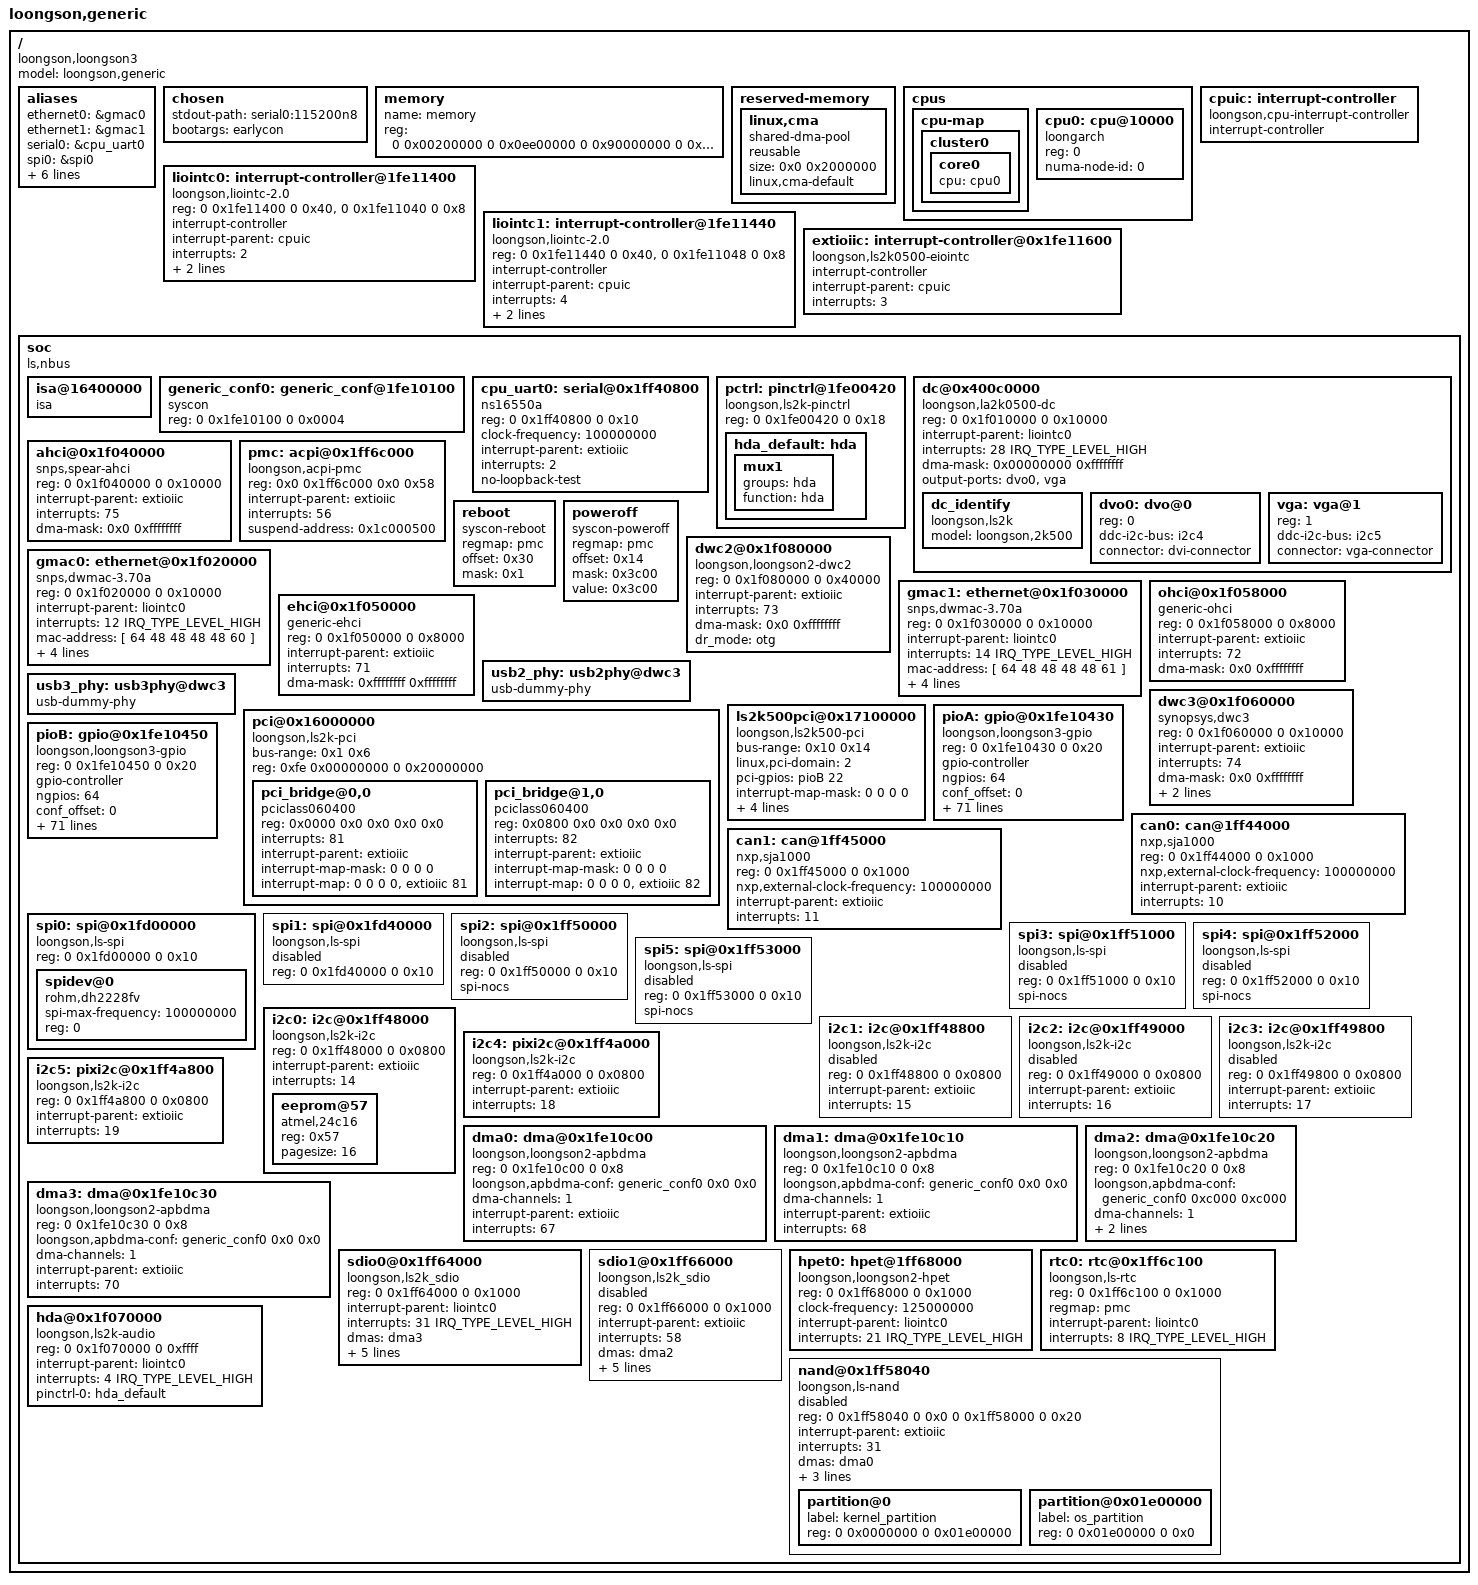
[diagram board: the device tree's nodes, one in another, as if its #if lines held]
#include <dt-bindings/interrupt-controller/irq.h>
#include <dt-bindings/gpio/gpio.h>

/dts-v1/;
/ {
	model = "loongson,generic";
	compatible = "loongson,loongson3";
	#address-cells = <2>;
	#size-cells = <2>;

	aliases {
		ethernet0 = &gmac0;
		ethernet1 = &gmac1;
		serial0 = &cpu_uart0;
		spi0 = &spi0;
		i2c0 = &i2c0;
		i2c1 = &i2c1;
		i2c2 = &i2c2;
		i2c3 = &i2c3;
		i2c4 = &i2c4;
		i2c5 = &i2c5;
	};

	chosen {
		stdout-path = "serial0:115200n8";
		bootargs = "earlycon";
	};

	memory {
		name = "memory";
		device_type = "memory";
		reg =  <0 0x00200000 0 0x0ee00000
			0 0x90000000 0 0x60000000>;
	};

	reserved-memory {
		#address-cells = <2>;
		#size-cells = <2>;
		ranges;

		linux,cma {
			compatible = "shared-dma-pool";
			reusable;
			size = <0x0 0x2000000>;
			linux,cma-default;
		};
	};

	cpus {
		#address-cells = <1>;
		#size-cells = <0>;
		cpu-map {
			cluster0 {
				core0 {
					cpu = <&cpu0>;
				};
			};
		};


		cpu0: cpu@10000 {
			device_type = "cpu";
			compatible = "loongarch";
			reg=<0>;
			numa-node-id = <0>;
		};

	};

	cpuic: interrupt-controller {
		compatible = "loongson,cpu-interrupt-controller";
		interrupt-controller;
		#interrupt-cells = <1>;
	};

	liointc0: interrupt-controller@1fe11400 {
		compatible = "loongson,liointc-2.0";
		reg = <0 0x1fe11400 0 0x40>,
		      <0 0x1fe11040 0 0x8>;
		reg-names = "main", "isr0";

		interrupt-controller;
		#interrupt-cells = <2>;
		interrupt-parent = <&cpuic>;
		interrupts = <2>;
		interrupt-names = "int0";

		loongson,parent_int_map = <0xffffffff>, /* int0 */
					<0x00000000>, /* int1 */
					<0x00000000>, /* int2 */
					<0x00000000>; /* int3 */
	};

	liointc1: interrupt-controller@1fe11440 {
		compatible = "loongson,liointc-2.0";
		reg = <0 0x1fe11440 0 0x40>,
		      <0 0x1fe11048 0 0x8>;
		reg-names = "main", "isr0";

		interrupt-controller;
		#interrupt-cells = <2>;

		interrupt-parent = <&cpuic>;
		interrupts = <4>;
		interrupt-names = "int2";

		loongson,parent_int_map = <0x00000000>, /* int0 */
					<0x00000000>, /* int1 */
					<0xffffffff>, /* int2 */
					<0x00000000>; /* int3 */
	};

	extioiic: interrupt-controller@0x1fe11600 {
		compatible = "loongson,ls2k0500-eiointc";
		interrupt-controller;
		#interrupt-cells = <1>;
		interrupt-parent = <&cpuic>;
		interrupts = <3>;
	};

	soc {
		compatible = "ls,nbus", "simple-bus";
		#address-cells = <2>;
		#size-cells = <2>;
		ranges = <0 0x10000000 0 0x10000000 0 0x10000000
			0 0x2000000  0 0x2000000  0 0x2000000
			0 0x20000000 0 0x20000000 0 0x10000000
			0 0x40000000 0 0x40000000 0 0x40000000
			0xfe 0x00000000 0xfe 0x00000000 0 0x40000000>;

		isa@16400000 {
			compatible = "isa";
			#size-cells = <1>;
			#address-cells = <2>;
			ranges = <1 0 0 0x16400000 0x4000>;
		};

		generic_conf0: generic_conf@1fe10100 {
			compatible = "syscon";
			reg = <0 0x1fe10100 0 0x0004>;
		};

		cpu_uart0: serial@0x1ff40800 {
			compatible = "ns16550a";
			reg = <0 0x1ff40800 0 0x10>;
			clock-frequency = <100000000>;
			interrupt-parent = <&extioiic>;
			interrupts = <2>;
			no-loopback-test;
		};
		pctrl:pinctrl@1fe00420 {
			compatible = "loongson,ls2k-pinctrl";
			reg = <0 0x1fe00420 0 0x18>;
			hda_default:hda {
				mux1 {
					groups ="hda";
					function ="hda";
				};
			};
		};

		dc@0x400c0000 {
			compatible = "loongson,la2k0500-dc", "loongson,display-subsystem";
			reg = <0 0x1f010000 0 0x10000>;
			interrupt-parent = <&liointc0>;
			interrupts = <28 IRQ_TYPE_LEVEL_HIGH>;
			dma-mask = <0x00000000 0xffffffff>;

			output-ports = <&dvo0 &vga>;

			#address-cells = <1>;
			#size-cells = <0>;

			dc_identify {
				model = "loongson,2k500";
				compatible = "loongson,ls2k";
			};

			dvo0: dvo@0 {
				/* 0 for connector 0 (DVO0) */
				reg = <0>;
				ddc-i2c-bus = <&i2c4>;
				connector = "dvi-connector";
				status = "ok";
			};

			vga: vga@1 {
				/* 1 for connector 1 (DVO1) */
				reg = <1>;
				ddc-i2c-bus = <&i2c5>;
				connector = "vga-connector";
				status = "ok";
			};
		};

		ahci@0x1f040000 {
			compatible = "snps,spear-ahci";
			reg = <0 0x1f040000 0 0x10000>;
			interrupt-parent = <&extioiic>;
			interrupts = <75>;
			dma-mask = <0x0 0xffffffff>;
		};

		pmc: acpi@0x1ff6c000 {
			compatible = "loongson,acpi-pmc", "syscon";
			reg = <0x0 0x1ff6c000 0x0 0x58>;
			interrupt-parent = <&extioiic>;
			interrupts = <56>;
			suspend-address = <0x1c000500>;
		};

		reboot {
			compatible ="syscon-reboot";
			regmap = <&pmc>;
			offset = <0x30>;
			mask = <0x1>;
		};

		poweroff {
			compatible ="syscon-poweroff";
			regmap = <&pmc>;
			offset = <0x14>;
			mask = <0x3c00>;
			value = <0x3c00>;
		};

		dwc2@0x1f080000 {
			compatible = "loongson,loongson2-dwc2";
			reg = <0 0x1f080000 0 0x40000>;
			interrupt-parent = <&extioiic>;
			interrupts = <73>;
			dma-mask = <0x0 0xffffffff>;
			dr_mode = "otg";
			/* Optional for that dr_mode = "host" or dr_mode = "peripheral" */
		};

		gmac0: ethernet@0x1f020000 {
			compatible = "snps,dwmac-3.70a";
			reg = <0 0x1f020000 0 0x10000>;
			interrupt-parent = <&liointc0>;
			interrupts = <12 IRQ_TYPE_LEVEL_HIGH>;
			interrupt-names = "macirq";
			mac-address = [ 64 48 48 48 48 60 ];/* [>mac 64:48:48:48:48:60 <]*/
			phy-mode = "rgmii";
			bus_id = <0x0>;
			phy_addr = <0xffffffff>;
			dma-mask = <0xffffffff 0xffffffff>;
		};

		gmac1: ethernet@0x1f030000 {
			compatible = "snps,dwmac-3.70a";
			reg = <0 0x1f030000 0 0x10000>;
			interrupt-parent = <&liointc0>;
			interrupts = <14 IRQ_TYPE_LEVEL_HIGH>;
			interrupt-names = "macirq";
			mac-address = [ 64 48 48 48 48 61 ];/* [>mac 64:48:48:48:48:61 <]*/
			phy-mode = "rgmii";
			bus_id = <0x1>;
			phy_addr = <0xffffffff>;
			dma-mask = <0xffffffff 0xffffffff>;
		};

		ohci@0x1f058000 {
			compatible = "generic-ohci";
			reg = <0 0x1f058000 0 0x8000>;
			interrupt-parent = <&extioiic>;
			interrupts = <72>;
			dma-mask = <0x0 0xffffffff>;
		};

		ehci@0x1f050000 {
			compatible = "generic-ehci";
			reg = <0 0x1f050000 0 0x8000>;
			interrupt-parent = <&extioiic>;
			interrupts = <71>;
			dma-mask = <0xffffffff 0xffffffff>;
		};

		usb2_phy: usb2phy@dwc3 {
			compatible = "usb-dummy-phy";
		};

		usb3_phy: usb3phy@dwc3 {
			compatible = "usb-dummy-phy";
		};

		dwc3@0x1f060000 {
			compatible = "synopsys,dwc3";
			reg = <0 0x1f060000 0 0x10000>;
			interrupt-parent = <&extioiic>;
			interrupts = <74>;
			dma-mask = <0x0 0xffffffff>;
			usb-phy = <&usb2_phy>, <&usb3_phy>;
			dr_mode = "host";
		};

		pci@0x16000000 {
			compatible = "loongson,ls2k-pci";
			#interrupt-cells = <1>;
			bus-range = <0x1 0x6>;
			#size-cells = <2>;
			#address-cells = <3>;

			reg = < 0xfe 0x00000000 0 0x20000000>;
			ranges = <0x02000000 0 0x40000000 0 0x40000000 0 0x40000000
				  0x01000000 0 0x00004000 0 0x16404000 0x0 0x4000>;

			pci_bridge@0,0 {
				compatible = "pciclass060400",
						   "pciclass0604";

				reg = <0x0000 0x0 0x0 0x0 0x0>;
				interrupts = <81>;
				interrupt-parent = <&extioiic>;

				#interrupt-cells = <1>;
				interrupt-map-mask = <0 0 0 0>;
				interrupt-map = <0 0 0 0 &extioiic 81>;
			};
			pci_bridge@1,0 {
				compatible = "pciclass060400",
						   "pciclass0604";

				reg = <0x0800 0x0 0x0 0x0 0x0>;
				interrupts = <82>;
				interrupt-parent = <&extioiic>;

				#interrupt-cells = <1>;
				interrupt-map-mask = <0 0 0 0>;
				interrupt-map = <0 0 0 0 &extioiic 82>;
			};
		};

#ifdef LS2K500_HAVE_PCI
		ls2k500pci@0x17100000 {
			compatible = "loongson,ls2k500-pci";
			#interrupt-cells = <1>;
			bus-range = <0x10 0x14>;
			#size-cells = <2>;
			#address-cells = <3>;
			linux,pci-domain = <2>;

#if 0
			pci-gpios = <&pioA 0 0>, <&pioA 1 0>;
			interrupt-map-mask = <0xf800 0 0 7>;
			interrupt-map =
				<0x0f8000 0 0 1 &liointc1 26 IRQ_TYPE_LEVEL_HIGH>, /* Slot 9 */
				<0x0f8000 0 0 2 &liointc1 26 IRQ_TYPE_LEVEL_HIGH>,
				<0x0f8000 0 0 3 &liointc1 26 IRQ_TYPE_LEVEL_HIGH>,
				<0x0f8000 0 0 4 &liointc1 26 IRQ_TYPE_LEVEL_HIGH>,
				<0x0f8800 0 0 1 &liointc1 26 IRQ_TYPE_LEVEL_HIGH>, /* Slot 10 */
				<0x0f8800 0 0 2 &liointc1 26 IRQ_TYPE_LEVEL_HIGH>,
				<0x0f8800 0 0 3 &liointc1 26 IRQ_TYPE_LEVEL_HIGH>,
				<0x0f8800 0 0 4 &liointc1 26 IRQ_TYPE_LEVEL_HIGH>;
#else
				pci-gpios = <&pioB 22 0>;
				interrupt-map-mask = <0 0 0 0>;
				interrupt-map = <0 0 0 0 &liointc1 28 IRQ_TYPE_LEVEL_HIGH>;
#endif
				reg = < 0x0 0x17100000 0 0x10000
					0x0 0x17110000 0 0x10000
					0x0 0x1fe11100 0 0x100 >;
			ranges = <0x02000000 0 0x20000000 0 0x20000000 0 0x10000000
				  0x01000000 0 0x00008000 0 0x17008000 0x0 0x4000>;
		};
#endif

		pioA:gpio@0x1fe10430 {
			compatible = "loongson,loongson3-gpio";
			reg = <0 0x1fe10430 0 0x20>;
			gpio-controller;
			#gpio-cells = <2>;
			ngpios = <64>;
			conf_offset = <0>;
			out_offset = <0x10>;
			in_offset = <0x8>;
			in_start_bit = <0>;
			inten_offset = <0xb0>;
			gpio_base = <0>;
			support_irq;
			interrupts-extended =
				/*
				 * Every 32 gpios share a interrupt line. We need to disable
				 * unnecessary GPIO interrupts in the firmware.
				 */
				<&liointc1 26 IRQ_TYPE_LEVEL_HIGH>,<&liointc1 26 IRQ_TYPE_LEVEL_HIGH>,<&liointc1 26 IRQ_TYPE_LEVEL_HIGH>,<&liointc1 26 IRQ_TYPE_LEVEL_HIGH>,
				<&liointc1 26 IRQ_TYPE_LEVEL_HIGH>,<&liointc1 26 IRQ_TYPE_LEVEL_HIGH>,<&liointc1 26 IRQ_TYPE_LEVEL_HIGH>,<&liointc1 26 IRQ_TYPE_LEVEL_HIGH>,
				<&liointc1 26 IRQ_TYPE_LEVEL_HIGH>,<&liointc1 26 IRQ_TYPE_LEVEL_HIGH>,<&liointc1 26 IRQ_TYPE_LEVEL_HIGH>,<&liointc1 26 IRQ_TYPE_LEVEL_HIGH>,
				<&liointc1 26 IRQ_TYPE_LEVEL_HIGH>,<&liointc1 26 IRQ_TYPE_LEVEL_HIGH>,<&liointc1 26 IRQ_TYPE_LEVEL_HIGH>,<&liointc1 26 IRQ_TYPE_LEVEL_HIGH>,
				<&liointc1 26 IRQ_TYPE_LEVEL_HIGH>,<&liointc1 26 IRQ_TYPE_LEVEL_HIGH>,<&liointc1 26 IRQ_TYPE_LEVEL_HIGH>,<&liointc1 26 IRQ_TYPE_LEVEL_HIGH>,
				<&liointc1 26 IRQ_TYPE_LEVEL_HIGH>,<&liointc1 26 IRQ_TYPE_LEVEL_HIGH>,<&liointc1 26 IRQ_TYPE_LEVEL_HIGH>,<&liointc1 26 IRQ_TYPE_LEVEL_HIGH>,
				<&liointc1 26 IRQ_TYPE_LEVEL_HIGH>,<&liointc1 26 IRQ_TYPE_LEVEL_HIGH>,<&liointc1 26 IRQ_TYPE_LEVEL_HIGH>,<&liointc1 26 IRQ_TYPE_LEVEL_HIGH>,
				<&liointc1 26 IRQ_TYPE_LEVEL_HIGH>,<&liointc1 26 IRQ_TYPE_LEVEL_HIGH>,<&liointc1 26 IRQ_TYPE_LEVEL_HIGH>,<&liointc1 26 IRQ_TYPE_LEVEL_HIGH>,
				<&liointc1 27 IRQ_TYPE_LEVEL_HIGH>,<&liointc1 27 IRQ_TYPE_LEVEL_HIGH>,<&liointc1 27 IRQ_TYPE_LEVEL_HIGH>,<&liointc1 27 IRQ_TYPE_LEVEL_HIGH>,
				<&liointc1 27 IRQ_TYPE_LEVEL_HIGH>,<&liointc1 27 IRQ_TYPE_LEVEL_HIGH>,<&liointc1 27 IRQ_TYPE_LEVEL_HIGH>,<&liointc1 27 IRQ_TYPE_LEVEL_HIGH>,
				<&liointc1 27 IRQ_TYPE_LEVEL_HIGH>,<&liointc1 27 IRQ_TYPE_LEVEL_HIGH>,<&liointc1 27 IRQ_TYPE_LEVEL_HIGH>,<&liointc1 27 IRQ_TYPE_LEVEL_HIGH>,
				<&liointc1 27 IRQ_TYPE_LEVEL_HIGH>,<&liointc1 27 IRQ_TYPE_LEVEL_HIGH>,<&liointc1 27 IRQ_TYPE_LEVEL_HIGH>,<&liointc1 27 IRQ_TYPE_LEVEL_HIGH>,
				<&liointc1 27 IRQ_TYPE_LEVEL_HIGH>,<&liointc1 27 IRQ_TYPE_LEVEL_HIGH>,<&liointc1 27 IRQ_TYPE_LEVEL_HIGH>,<&liointc1 27 IRQ_TYPE_LEVEL_HIGH>,
				<&liointc1 27 IRQ_TYPE_LEVEL_HIGH>,<&liointc1 27 IRQ_TYPE_LEVEL_HIGH>,<&liointc1 27 IRQ_TYPE_LEVEL_HIGH>,<&liointc1 27 IRQ_TYPE_LEVEL_HIGH>,
				<&liointc1 27 IRQ_TYPE_LEVEL_HIGH>,<&liointc1 27 IRQ_TYPE_LEVEL_HIGH>,<&liointc1 27 IRQ_TYPE_LEVEL_HIGH>,<&liointc1 27 IRQ_TYPE_LEVEL_HIGH>,
				<&liointc1 27 IRQ_TYPE_LEVEL_HIGH>,<&liointc1 27 IRQ_TYPE_LEVEL_HIGH>,<&liointc1 27 IRQ_TYPE_LEVEL_HIGH>,<&liointc1 27 IRQ_TYPE_LEVEL_HIGH>;
		};

		pioB:gpio@0x1fe10450 {
			compatible = "loongson,loongson3-gpio";
			reg = <0 0x1fe10450 0 0x20>;
			gpio-controller;
			#gpio-cells = <2>;
			ngpios = <64>;
			conf_offset = <0>;
			out_offset = <0x10>;
			in_offset = <0x8>;
			in_start_bit = <0>;
			inten_offset = <0x98>;
			gpio_base = <64>;
			support_irq;
			interrupts-extended  =
				/*
				 * Every 32 gpios share a interrupt line. We need to disable
				 * unnecessary GPIO interrupts in the firmware.
				 */
				<&liointc1 28 IRQ_TYPE_LEVEL_HIGH>,<&liointc1 28 IRQ_TYPE_LEVEL_HIGH>,<&liointc1 28 IRQ_TYPE_LEVEL_HIGH>,<&liointc1 28 IRQ_TYPE_LEVEL_HIGH>,
				<&liointc1 28 IRQ_TYPE_LEVEL_HIGH>,<&liointc1 28 IRQ_TYPE_LEVEL_HIGH>,<&liointc1 28 IRQ_TYPE_LEVEL_HIGH>,<&liointc1 28 IRQ_TYPE_LEVEL_HIGH>,
				<&liointc1 28 IRQ_TYPE_LEVEL_HIGH>,<&liointc1 28 IRQ_TYPE_LEVEL_HIGH>,<&liointc1 28 IRQ_TYPE_LEVEL_HIGH>,<&liointc1 28 IRQ_TYPE_LEVEL_HIGH>,
				<&liointc1 28 IRQ_TYPE_LEVEL_HIGH>,<&liointc1 28 IRQ_TYPE_LEVEL_HIGH>,<&liointc1 28 IRQ_TYPE_LEVEL_HIGH>,<&liointc1 28 IRQ_TYPE_LEVEL_HIGH>,
				<&liointc1 28 IRQ_TYPE_LEVEL_HIGH>,<&liointc1 28 IRQ_TYPE_LEVEL_HIGH>,<&liointc1 28 IRQ_TYPE_LEVEL_HIGH>,<&liointc1 28 IRQ_TYPE_LEVEL_HIGH>,
				<&liointc1 28 IRQ_TYPE_LEVEL_HIGH>,<&liointc1 28 IRQ_TYPE_LEVEL_HIGH>,<&liointc1 28 IRQ_TYPE_LEVEL_HIGH>,<&liointc1 28 IRQ_TYPE_LEVEL_HIGH>,
				<&liointc1 28 IRQ_TYPE_LEVEL_HIGH>,<&liointc1 28 IRQ_TYPE_LEVEL_HIGH>,<&liointc1 28 IRQ_TYPE_LEVEL_HIGH>,<&liointc1 28 IRQ_TYPE_LEVEL_HIGH>,
				<&liointc1 28 IRQ_TYPE_LEVEL_HIGH>,<&liointc1 28 IRQ_TYPE_LEVEL_HIGH>,<&liointc1 28 IRQ_TYPE_LEVEL_HIGH>,<&liointc1 28 IRQ_TYPE_LEVEL_HIGH>,
				<&liointc1 29 IRQ_TYPE_LEVEL_HIGH>,<&liointc1 29 IRQ_TYPE_LEVEL_HIGH>,<&liointc1 29 IRQ_TYPE_LEVEL_HIGH>,<&liointc1 29 IRQ_TYPE_LEVEL_HIGH>,
				<&liointc1 29 IRQ_TYPE_LEVEL_HIGH>,<&liointc1 29 IRQ_TYPE_LEVEL_HIGH>,<&liointc1 29 IRQ_TYPE_LEVEL_HIGH>,<&liointc1 29 IRQ_TYPE_LEVEL_HIGH>,
				<&liointc1 29 IRQ_TYPE_LEVEL_HIGH>,<&liointc1 29 IRQ_TYPE_LEVEL_HIGH>,<&liointc1 29 IRQ_TYPE_LEVEL_HIGH>,<&liointc1 29 IRQ_TYPE_LEVEL_HIGH>,
				<&liointc1 29 IRQ_TYPE_LEVEL_HIGH>,<&liointc1 29 IRQ_TYPE_LEVEL_HIGH>,<&liointc1 29 IRQ_TYPE_LEVEL_HIGH>,<&liointc1 29 IRQ_TYPE_LEVEL_HIGH>,
				<&liointc1 29 IRQ_TYPE_LEVEL_HIGH>,<&liointc1 29 IRQ_TYPE_LEVEL_HIGH>,<&liointc1 29 IRQ_TYPE_LEVEL_HIGH>,<&liointc1 29 IRQ_TYPE_LEVEL_HIGH>,
				<&liointc1 29 IRQ_TYPE_LEVEL_HIGH>,<&liointc1 29 IRQ_TYPE_LEVEL_HIGH>,<&liointc1 29 IRQ_TYPE_LEVEL_HIGH>,<&liointc1 29 IRQ_TYPE_LEVEL_HIGH>,
				<&liointc1 29 IRQ_TYPE_LEVEL_HIGH>,<&liointc1 29 IRQ_TYPE_LEVEL_HIGH>,<&liointc1 29 IRQ_TYPE_LEVEL_HIGH>,<&liointc1 29 IRQ_TYPE_LEVEL_HIGH>,
				<&liointc1 29 IRQ_TYPE_LEVEL_HIGH>,<&liointc1 29 IRQ_TYPE_LEVEL_HIGH>,<&liointc1 29 IRQ_TYPE_LEVEL_HIGH>,<&liointc1 29 IRQ_TYPE_LEVEL_HIGH>;
		};

		can0: can@1ff44000 {
			compatible = "nxp,sja1000";
			reg = <0 0x1ff44000 0 0x1000>;
			nxp,external-clock-frequency = <100000000>;
			interrupt-parent = <&extioiic>;
			interrupts = <10>;
		};

		can1: can@1ff45000 {
			compatible = "nxp,sja1000";
			reg = <0 0x1ff45000 0 0x1000>;
			nxp,external-clock-frequency = <100000000>;
			interrupt-parent = <&extioiic>;
			interrupts = <11>;
		};

		spi0: spi@0x1fd00000 {
			compatible = "loongson,ls-spi";
			#address-cells = <1>;
			#size-cells = <0>;
			reg = <0 0x1fd00000 0 0x10>;
			spidev@0 {
				compatible = "rohm,dh2228fv";
				spi-max-frequency = <100000000>;
				reg = <0>;
			};
		};

		spi1: spi@0x1fd40000 {
			compatible = "loongson,ls-spi";
			reg = <0 0x1fd40000 0 0x10>;
			status = "disabled";
		};

		/* SPI2~5 has only one CS, which is set by SPCS */
		spi2: spi@0x1ff50000 {
			compatible = "loongson,ls-spi";
			reg = <0 0x1ff50000 0 0x10>;
			spi-nocs;
			status = "disabled";
		};

		spi3: spi@0x1ff51000 {
			compatible = "loongson,ls-spi";
			reg = <0 0x1ff51000 0 0x10>;
			spi-nocs;
			status = "disabled";
		};

		spi4: spi@0x1ff52000 {
			compatible = "loongson,ls-spi";
			reg = <0 0x1ff52000 0 0x10>;
			spi-nocs;
			status = "disabled";
		};

		spi5: spi@0x1ff53000 {
			compatible = "loongson,ls-spi";
			reg = <0 0x1ff53000 0 0x10>;
			spi-nocs;
			status = "disabled";
		};

		i2c0: i2c@0x1ff48000 {
			compatible = "loongson,ls2k-i2c";
			#address-cells = <1>;
			#size-cells = <0>;
			reg = <0 0x1ff48000 0 0x0800>;
			interrupt-parent = <&extioiic>;
			interrupts = <14>;
			eeprom@57 {
				compatible = "atmel,24c16";
				reg = <0x57>;
				pagesize = <16>;
			};
		};

		i2c1: i2c@0x1ff48800 {
			compatible = "loongson,ls2k-i2c";
			reg = <0 0x1ff48800 0 0x0800>;
			interrupt-parent = <&extioiic>;
			interrupts = <15>;
			status = "disabled";
		};

		i2c2: i2c@0x1ff49000 {
			compatible = "loongson,ls2k-i2c";
			reg = <0 0x1ff49000 0 0x0800>;
			interrupt-parent = <&extioiic>;
			interrupts = <16>;
			status = "disabled";
		};

		i2c3: i2c@0x1ff49800 {
			compatible = "loongson,ls2k-i2c";
			reg = <0 0x1ff49800 0 0x0800>;
			interrupt-parent = <&extioiic>;
			interrupts = <17>;
			status = "disabled";
		};

		i2c4: pixi2c@0x1ff4a000{
			compatible = "loongson,ls2k-i2c";
			reg = <0 0x1ff4a000 0 0x0800>;
			interrupt-parent = <&extioiic>;
			interrupts = <18>;
		};

		i2c5: pixi2c@0x1ff4a800 {
			compatible = "loongson,ls2k-i2c";
			reg = <0 0x1ff4a800 0 0x0800>;
			interrupt-parent = <&extioiic>;
			interrupts = <19>;
		};

		dma0: dma@0x1fe10c00 {
			compatible = "loongson,loongson2-apbdma";
			reg = <0 0x1fe10c00 0 0x8>;
			loongson,apbdma-conf = <&generic_conf0 0x0 0x0>;
			#dma-cells = <0>;
			dma-channels = <1>;
			interrupt-parent = <&extioiic>;
			interrupts = <67>;
		};

		dma1: dma@0x1fe10c10 {
			compatible = "loongson,loongson2-apbdma";
			reg = <0 0x1fe10c10 0 0x8>;
			loongson,apbdma-conf = <&generic_conf0 0x0 0x0>;
			#dma-cells = <0>;
			dma-channels = <1>;
			interrupt-parent = <&extioiic>;
			interrupts = <68>;
		};

		dma2: dma@0x1fe10c20 {
			compatible = "loongson,loongson2-apbdma";
			reg = <0 0x1fe10c20 0 0x8>;
			loongson,apbdma-conf = <&generic_conf0 0xc000 0xc000>; /* 0xc000 for sdio1*/
			#dma-cells = <0>;
			dma-channels = <1>;
			interrupt-parent = <&extioiic>;
			interrupts = <69>;
		};

		dma3: dma@0x1fe10c30 {
			compatible = "loongson,loongson2-apbdma";
			reg = <0 0x1fe10c30 0 0x8>;
			loongson,apbdma-conf = <&generic_conf0 0x0 0x0>;
			#dma-cells = <0>;
			dma-channels = <1>;
			interrupt-parent = <&extioiic>;
			interrupts = <70>;
		};

		sdio0@0x1ff64000 {
			#address-cells = <2>;
			compatible = "loongson,ls2k_sdio";
			reg = <0 0x1ff64000 0 0x1000>;
			interrupt-parent = <&liointc0>;
			interrupts = <31 IRQ_TYPE_LEVEL_HIGH>;
			interrupt-names = "ls2k_mci_irq";
			dmas = <&dma3>;
			dma-names = "sdio_rw";
			dma-mask = <0xffffffff 0xffffffff>;
			clock-frequency = <0 125000000>;
			bus-width = <4>;
			cd-debounce-delay-ms = <0>;
			/* cd-gpios = <&pioA 44 GPIO_ACTIVE_LOW>; */
			/* Use this pin for irq hotplug detect SD card that */
			/* need rework hardware and remove non-removable */
			non-removable;
			/* broken-cd; */
			/* broken-cd for polling mode to hotplug detect SD */
			/* card but consumes lots of CPU resources */
		};

		sdio1@0x1ff66000 {
			#address-cells = <2>;
			compatible = "loongson,ls2k_sdio";
			reg = <0 0x1ff66000 0 0x1000>;
			interrupt-parent = <&extioiic>;
			interrupts = <58>;
			interrupt-names = "ls2k_mci_irq";
			dmas = <&dma2>;
			dma-names = "sdio_rw";
			dma-mask = <0xffffffff 0xffffffff>;
			clock-frequency = <0 125000000>;
			bus-width = <4>;
			cd-debounce-delay-ms = <0>;

			cd-gpios = <&pioB 22 GPIO_ACTIVE_LOW>;
			status = "disabled";
		};

		hpet0: hpet@1ff68000{
			compatible = "loongson,loongson2-hpet";
			reg = <0 0x1ff68000 0 0x1000>;
			clock-frequency = <125000000>;
			interrupt-parent = <&liointc0>;
			interrupts = <21 IRQ_TYPE_LEVEL_HIGH>;
		};

		rtc0: rtc@0x1ff6c100{
			#address-cells = <1>;
			#size-cells = <1>;
			compatible = "loongson,ls-rtc";
			reg = <0 0x1ff6c100 0 0x1000>;
			regmap = <&pmc>;
			interrupt-parent = <&liointc0>;
			interrupts = <8 IRQ_TYPE_LEVEL_HIGH>;
		};

		hda@0x1f070000 {
			compatible = "loongson,ls2k-audio";
			reg = <0 0x1f070000 0 0xffff>;
			interrupt-parent = <&liointc0>;
			interrupts = <4 IRQ_TYPE_LEVEL_HIGH>;
			pinctrl-0 = <&hda_default>;
			pinctrl-names = "default";
		};

		nand@0x1ff58040 {
			compatible = "loongson,ls-nand";
			reg = <0 0x1ff58040 0 0x0
				0 0x1ff58000 0 0x20>;
			interrupt-parent = <&extioiic>;
			interrupts = <31>;
			interrupt-names = "nand_irq";
			dmas = <&dma0>;
			dma-names = "nand_rw";
			dma-mask = <0xffffffff 0xffffffff>;
			#address-cells = <2>;
			#size-cells = <2>;
			nand-cs = <0x0>;
			status = "disabled";

			number-of-parts = <0x2>;
			partition@0 {
				label = "kernel_partition";
				reg = <0 0x0000000 0 0x01e00000>;
			};
			partition@0x01e00000 {
				label = "os_partition";
				reg = <0 0x01e00000 0 0x0>;
			};
		};
	};
};
